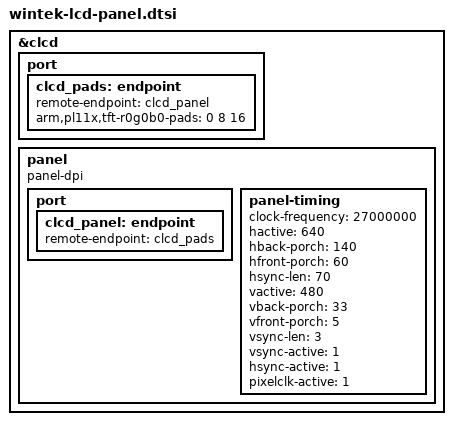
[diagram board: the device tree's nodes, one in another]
/*
 * Wintek LCD module model for BCM ENTPHN
 */

&clcd {
	status = "okay";
	port {
		clcd_pads: endpoint {
			remote-endpoint = <&clcd_panel>;
			arm,pl11x,tft-r0g0b0-pads = <0 8 16>;
		};
	};
	panel {
		compatible = "panel-dpi";
		port {
			clcd_panel: endpoint {
				remote-endpoint = <&clcd_pads>;
			};
		};
		panel-timing {
			clock-frequency = <27000000>;
			hactive = <640>;
			hback-porch = <140>;
			hfront-porch = <60>;
			hsync-len = <70>;
			vactive = <480>;
			vback-porch = <33>;
			vfront-porch = <5>;
			vsync-len = <3>;
			vsync-active = <1>;
			hsync-active = <1>;
			pixelclk-active = <1>;
		};
	};
};
